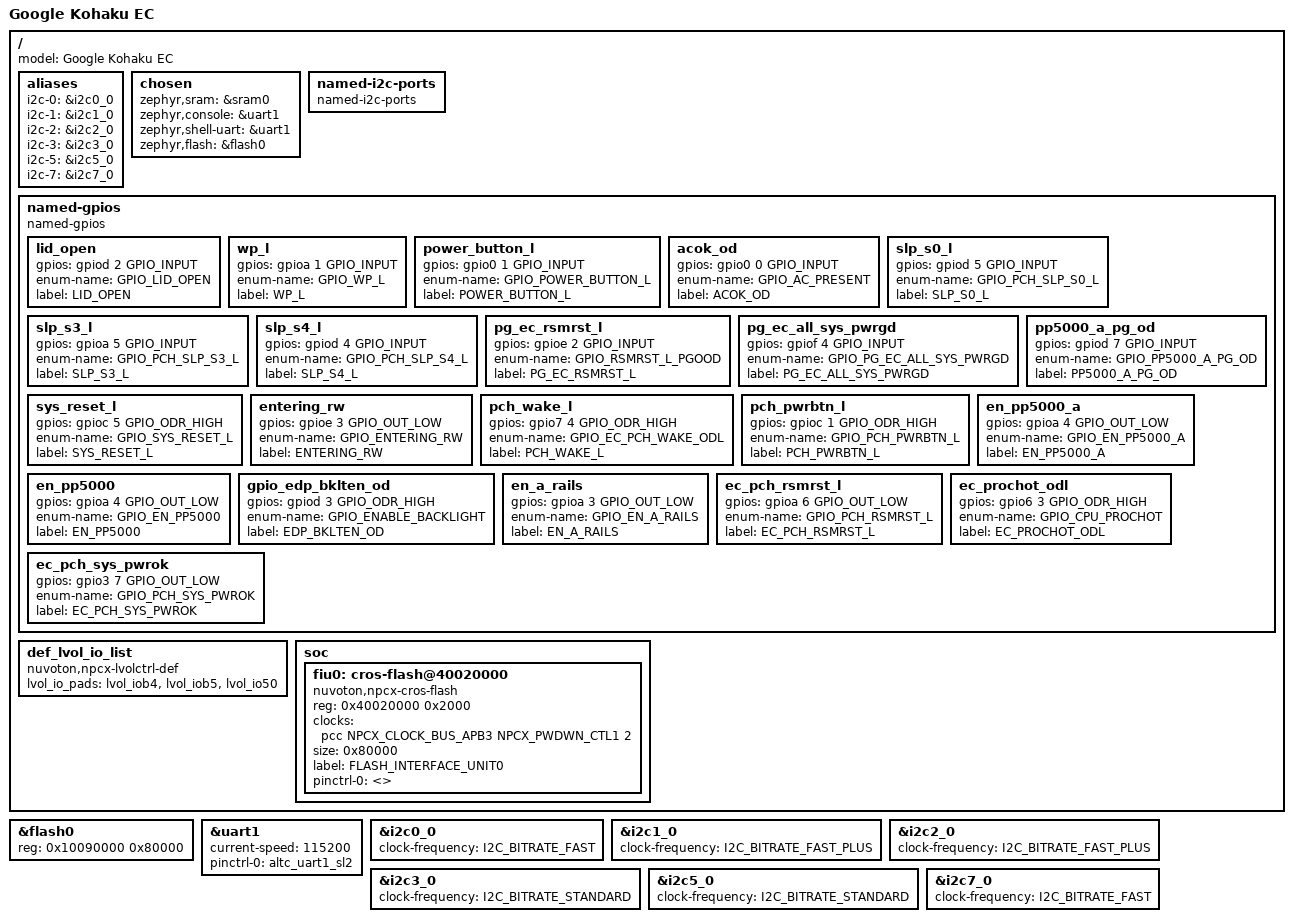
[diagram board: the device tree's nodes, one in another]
/* Copyright 2021 The Chromium OS Authors. All rights reserved.
 * Use of this source code is governed by a BSD-style license that can be
 * found in the LICENSE file.
 */

/dts-v1/;

#include <cros/nuvoton/npcx.dtsi>
#include <dt-bindings/gpio_defines.h>
#include <nuvoton/npcx7m6fb.dtsi>

/ {
	model = "Google Kohaku EC";

	aliases {
		i2c-0 = &i2c0_0;
		i2c-1 = &i2c1_0;
		i2c-2 = &i2c2_0;
		i2c-3 = &i2c3_0;
		i2c-5 = &i2c5_0;
		i2c-7 = &i2c7_0;
	};

	chosen {
		zephyr,sram = &sram0;
		zephyr,console = &uart1;
		zephyr,shell-uart = &uart1;
		zephyr,flash = &flash0;
	};

	named-i2c-ports {
		compatible = "named-i2c-ports";
	};

	named-gpios {
		compatible = "named-gpios";

		lid_open {
			gpios = <&gpiod 2 GPIO_INPUT>;
			enum-name = "GPIO_LID_OPEN";
			label = "LID_OPEN";
		};
		wp_l {
			gpios = <&gpioa 1 GPIO_INPUT>;
			enum-name = "GPIO_WP_L";
			label = "WP_L";
		};
		power_button_l {
			gpios = <&gpio0 1 GPIO_INPUT>;
			enum-name = "GPIO_POWER_BUTTON_L";
			label = "POWER_BUTTON_L";
		};
		acok_od {
			gpios = <&gpio0 0 GPIO_INPUT>;
			enum-name = "GPIO_AC_PRESENT";
			label = "ACOK_OD";
		};
		slp_s0_l {
			gpios = <&gpiod 5 GPIO_INPUT>;
			enum-name = "GPIO_PCH_SLP_S0_L";
			label = "SLP_S0_L";
		};
		slp_s3_l {
			gpios = <&gpioa 5 GPIO_INPUT>;
			enum-name = "GPIO_PCH_SLP_S3_L";
			label = "SLP_S3_L";
		};
		slp_s4_l {
			gpios = <&gpiod 4 GPIO_INPUT>;
			enum-name = "GPIO_PCH_SLP_S4_L";
			label = "SLP_S4_L";
		};
		pg_ec_rsmrst_l {
			gpios = <&gpioe 2 GPIO_INPUT>;
			enum-name = "GPIO_RSMRST_L_PGOOD";
			label = "PG_EC_RSMRST_L";
		};
		pg_ec_all_sys_pwrgd {
			gpios = <&gpiof 4 GPIO_INPUT>;
			enum-name = "GPIO_PG_EC_ALL_SYS_PWRGD";
			label = "PG_EC_ALL_SYS_PWRGD";
		};
		pp5000_a_pg_od {
			gpios = <&gpiod 7 GPIO_INPUT>;
			enum-name = "GPIO_PP5000_A_PG_OD";
			label = "PP5000_A_PG_OD";
		};
		sys_reset_l {
			gpios = <&gpioc 5 GPIO_ODR_HIGH>;
			enum-name = "GPIO_SYS_RESET_L";
			label = "SYS_RESET_L";
		};
		entering_rw {
			gpios = <&gpioe 3 GPIO_OUT_LOW>;
			enum-name = "GPIO_ENTERING_RW";
			label = "ENTERING_RW";
		};
		pch_wake_l {
			gpios = <&gpio7 4 GPIO_ODR_HIGH>;
			enum-name = "GPIO_EC_PCH_WAKE_ODL";
			label = "PCH_WAKE_L";
		};
		pch_pwrbtn_l {
			gpios = <&gpioc 1 GPIO_ODR_HIGH>;
			enum-name = "GPIO_PCH_PWRBTN_L";
			label = "PCH_PWRBTN_L";
		};
		en_pp5000_a {
			gpios = <&gpioa 4 GPIO_OUT_LOW>;
			enum-name = "GPIO_EN_PP5000_A";
			label = "EN_PP5000_A";
		};
		en_pp5000 {
			gpios = <&gpioa 4 GPIO_OUT_LOW>;
			enum-name = "GPIO_EN_PP5000";
			label = "EN_PP5000";
		};
		gpio_edp_bklten_od {
			gpios = <&gpiod 3 GPIO_ODR_HIGH>;
			enum-name = "GPIO_ENABLE_BACKLIGHT";
			label = "EDP_BKLTEN_OD";
		};
		en_a_rails {
			gpios = <&gpioa 3 GPIO_OUT_LOW>;
			enum-name = "GPIO_EN_A_RAILS";
			label = "EN_A_RAILS";
		};
		ec_pch_rsmrst_l {
			gpios = <&gpioa 6 GPIO_OUT_LOW>;
			enum-name = "GPIO_PCH_RSMRST_L";
			label = "EC_PCH_RSMRST_L";
		};
		ec_prochot_odl {
			gpios = <&gpio6 3 GPIO_ODR_HIGH>;
			enum-name = "GPIO_CPU_PROCHOT";
			label = "EC_PROCHOT_ODL";
		};
		ec_pch_sys_pwrok {
			gpios = <&gpio3 7 GPIO_OUT_LOW>;
			enum-name = "GPIO_PCH_SYS_PWROK";
			label = "EC_PCH_SYS_PWROK";
		};
	};

	def_lvol_io_list {
		compatible = "nuvoton,npcx-lvolctrl-def";
		lvol_io_pads = <&lvol_iob4 &lvol_iob5 /* I2C_SDA0 & SCL0 */
		                &lvol_io50>;          /* GPIO50 */
	};

	soc {
		fiu0: cros-flash@40020000 {
			compatible = "nuvoton,npcx-cros-flash";
			reg = <0x40020000 0x2000>;
			clocks = <&pcc NPCX_CLOCK_BUS_APB3 NPCX_PWDWN_CTL1 2>;
			size = <0x80000>;
			label = "FLASH_INTERFACE_UNIT0";
			pinctrl-0 = <>;
		};
	};
};

/* Update flash size to 512KB from 196KB since we are using C variant */
&flash0 {
	reg = <0x10090000 0x80000>;
};

&uart1 {
	status = "okay";
	current-speed = <115200>;
	pinctrl-0 = <&altc_uart1_sl2>; /* Use UART1_SL2 ie. PIN64.65 */
};

&i2c0_0 {
	status = "okay";
	clock-frequency = <I2C_BITRATE_FAST>;
};

&i2c1_0 {
	status = "okay";
	clock-frequency = <I2C_BITRATE_FAST_PLUS>;
};

&i2c2_0 {
	status = "okay";
	clock-frequency = <I2C_BITRATE_FAST_PLUS>;
};

&i2c3_0 {
	status = "okay";
	clock-frequency = <I2C_BITRATE_STANDARD>;
};

&i2c5_0 {
	status = "okay";
	clock-frequency = <I2C_BITRATE_STANDARD>;
};

&i2c7_0 {
	status = "okay";
	clock-frequency = <I2C_BITRATE_FAST>;
};
